# dsPIC33FJ64GS606 register map
Vendor: Microchip; Series: dsPIC33FJ64GS; File version: 1.4.228
Registers are 16-bit, read-write, no defined reset value unless marked. A register's access mark holds for its fields unless they carry their own. Offsets are from the block's base; [hi:lo] are bit positions; {n}, {i} and the like mark numbered series.

## CMP4 — CMP4 peripheral registers
Base 0x0000054C
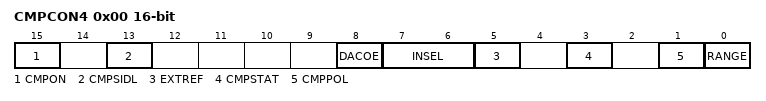
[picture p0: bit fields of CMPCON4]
0x00 CMPCON4
  [15] CMPON — CMPCON4 field CMPON
  [13] CMPSIDL — CMPCON4 field CMPSIDL
  [8] DACOE — CMPCON4 field DACOE
  [7:6] INSEL — CMPCON4 field INSEL
  [5] EXTREF — CMPCON4 field EXTREF
  [3] CMPSTAT — CMPCON4 field CMPSTAT
  [1] CMPPOL — CMPCON4 field CMPPOL
  [0] RANGE — CMPCON4 field RANGE
0x02 CMPDAC4
  [9:0] CMREF — CMPDAC4 field CMREF

## CLOCK — CLOCK peripheral registers
Base 0x00000740
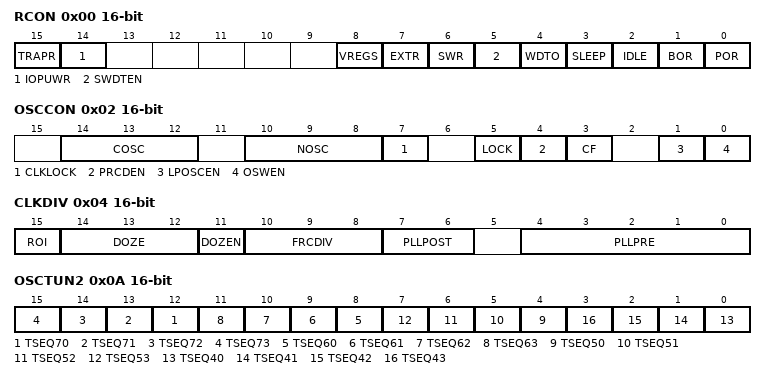
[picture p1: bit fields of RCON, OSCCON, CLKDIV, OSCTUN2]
0x00 RCON
  [15] TRAPR — RCON field TRAPR
  [14] IOPUWR — RCON field IOPUWR
  [8] VREGS — RCON field VREGS
  [7] EXTR — RCON field EXTR
  [6] SWR — RCON field SWR
  [5] SWDTEN — RCON field SWDTEN
  [4] WDTO — RCON field WDTO
  [3] SLEEP — RCON field SLEEP
  [2] IDLE — RCON field IDLE
  [1] BOR — RCON field BOR
  [0] POR — RCON field POR
0x02 OSCCON
  [14:12] COSC — OSCCON field COSC
  [10:8] NOSC — OSCCON field NOSC
  [7] CLKLOCK — OSCCON field CLKLOCK
  [5] LOCK — OSCCON field LOCK
  [4] PRCDEN — OSCCON field PRCDEN
  [3] CF — OSCCON field CF
  [1] LPOSCEN — OSCCON field LPOSCEN
  [0] OSWEN — OSCCON field OSWEN
0x04 CLKDIV
  [15] ROI — CLKDIV field ROI
  [14:12] DOZE — CLKDIV field DOZE
  [11] DOZEN — CLKDIV field DOZEN
  [10:8] FRCDIV — CLKDIV field FRCDIV
  [7:6] PLLPOST — CLKDIV field PLLPOST
  [4:0] PLLPRE — CLKDIV field PLLPRE
0x06 PLLFBD
  [8:0] PLLDIV — PLLFBD field PLLDIV
0x08 OSCTUN
  [n-18] TSEQ{n} (n=30..33) — OSCTUN field TSEQ{n}
  [n-12] TSEQ{n} (n=20..23) — OSCTUN field TSEQ{n}
  [n-6] TSEQ{n} (n=10..13) — OSCTUN field TSEQ{n}
  [5:0] TUN — OSCTUN field TUN
0x0A OSCTUN2
  [n-58] TSEQ{n} (n=70..73) — OSCTUN2 field TSEQ{n}
  [n-52] TSEQ{n} (n=60..63) — OSCTUN2 field TSEQ{n}
  [n-46] TSEQ{n} (n=50..53) — OSCTUN2 field TSEQ{n}
  [n-40] TSEQ{n} (n=40..43) — OSCTUN2 field TSEQ{n}
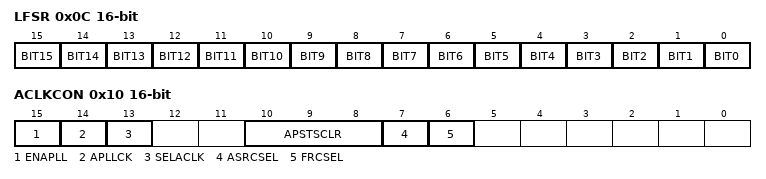
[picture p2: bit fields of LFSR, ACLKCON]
0x0C LFSR
  [n] BIT{n} (n=0..15) — LFSR bit {n}
0x0E REFOCON
  [15] ROON — REFOCON field ROON
  [13] ROSIDL — REFOCON field ROSIDL
  [13] ROSSLP — REFOCON field ROSSLP
  [12] ROSEL — REFOCON field ROSEL
  [11:8] RODIV — REFOCON field RODIV
0x10 ACLKCON
  [15] ENAPLL — ACLKCON field ENAPLL
  [14] APLLCK — ACLKCON field APLLCK
  [13] SELACLK — ACLKCON field SELACLK
  [10:8] APSTSCLR — ACLKCON field APSTSCLR
  [7] ASRCSEL — ACLKCON field ASRCSEL
  [6] FRCSEL — ACLKCON field FRCSEL

## NVM — NVM peripheral registers
Base 0x00000760
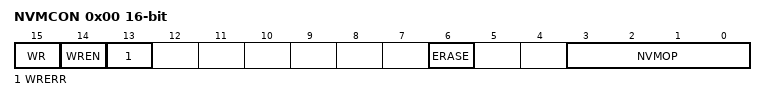
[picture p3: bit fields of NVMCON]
0x00 NVMCON
  [15] WR — NVMCON field WR
  [14] WREN — NVMCON field WREN
  [13] WRERR — NVMCON field WRERR
  [6] ERASE — NVMCON field ERASE
  [3:0] NVMOP — NVMCON field NVMOP
0x06 NVMKEY
  [15:0] NVMKEY — NVMKEY register value

## PMD — PMD peripheral registers
Base 0x00000770
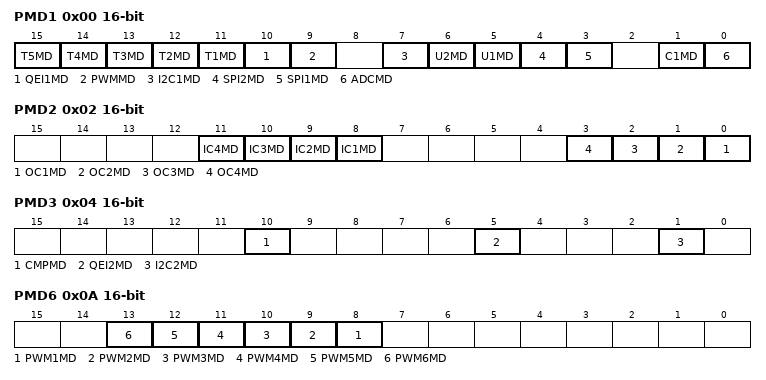
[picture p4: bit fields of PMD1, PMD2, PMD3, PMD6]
0x00 PMD1
  [n+10] T{n}MD (n=1..5) — PMD1 field T{n}MD
  [10] QEI1MD — PMD1 field QEI1MD
  [9] PWMMD — PMD1 field PWMMD
  [7] I2C1MD — PMD1 field I2C1MD
  [6] U2MD — PMD1 field U2MD
  [5] U1MD — PMD1 field U1MD
  [4] SPI2MD — PMD1 field SPI2MD
  [3] SPI1MD — PMD1 field SPI1MD
  [1] C1MD — PMD1 field C1MD
  [0] ADCMD — PMD1 field ADCMD
0x02 PMD2
  [n+7] IC{n}MD (n=1..4) — PMD2 field IC{n}MD
  [n-1] OC{n}MD (n=1..4) — PMD2 field OC{n}MD
0x04 PMD3
  [10] CMPMD — PMD3 field CMPMD
  [5] QEI2MD — PMD3 field QEI2MD
  [1] I2C2MD — PMD3 field I2C2MD
0x06 PMD4
  [3] REFOMD — PMD4 field REFOMD
0x0A PMD6
  [n+7] PWM{n}MD (n=1..6) — PMD6 field PWM{n}MD
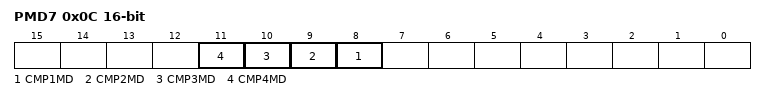
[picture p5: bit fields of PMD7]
0x0C PMD7
  [n+7] CMP{n}MD (n=1..4) — PMD7 field CMP{n}MD

## CONFIG — Configuration words stored in program space
Base 0x00F80000
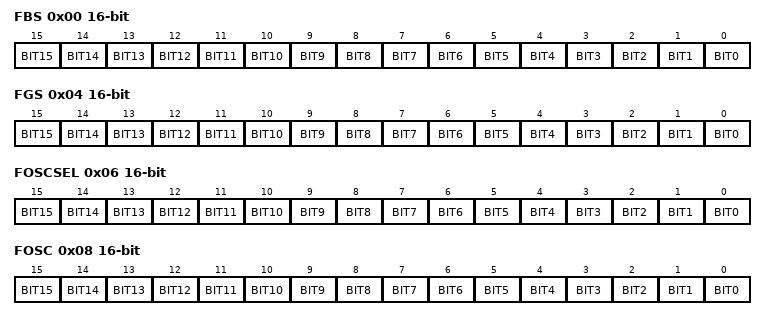
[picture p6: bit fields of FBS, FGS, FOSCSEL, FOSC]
0x00 FBS — Configuration word
  [n] BIT{n} (n=0..15) — FBS bit {n}
0x04 FGS — Configuration word
  [n] BIT{n} (n=0..15) — FGS bit {n}
0x06 FOSCSEL — Configuration word
  [n] BIT{n} (n=0..15) — FOSCSEL bit {n}
0x08 FOSC — Configuration word
  [n] BIT{n} (n=0..15) — FOSC bit {n}
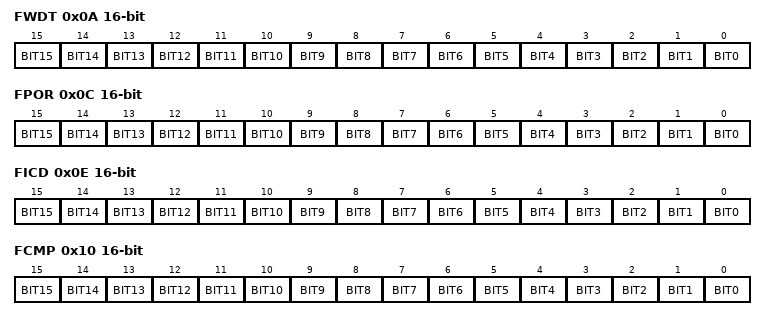
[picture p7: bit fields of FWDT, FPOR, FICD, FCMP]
0x0A FWDT — Configuration word
  [n] BIT{n} (n=0..15) — FWDT bit {n}
0x0C FPOR — Configuration word
  [n] BIT{n} (n=0..15) — FPOR bit {n}
0x0E FICD — Configuration word
  [n] BIT{n} (n=0..15) — FICD bit {n}
0x10 FCMP — Configuration word
  [n] BIT{n} (n=0..15) — FCMP bit {n}
